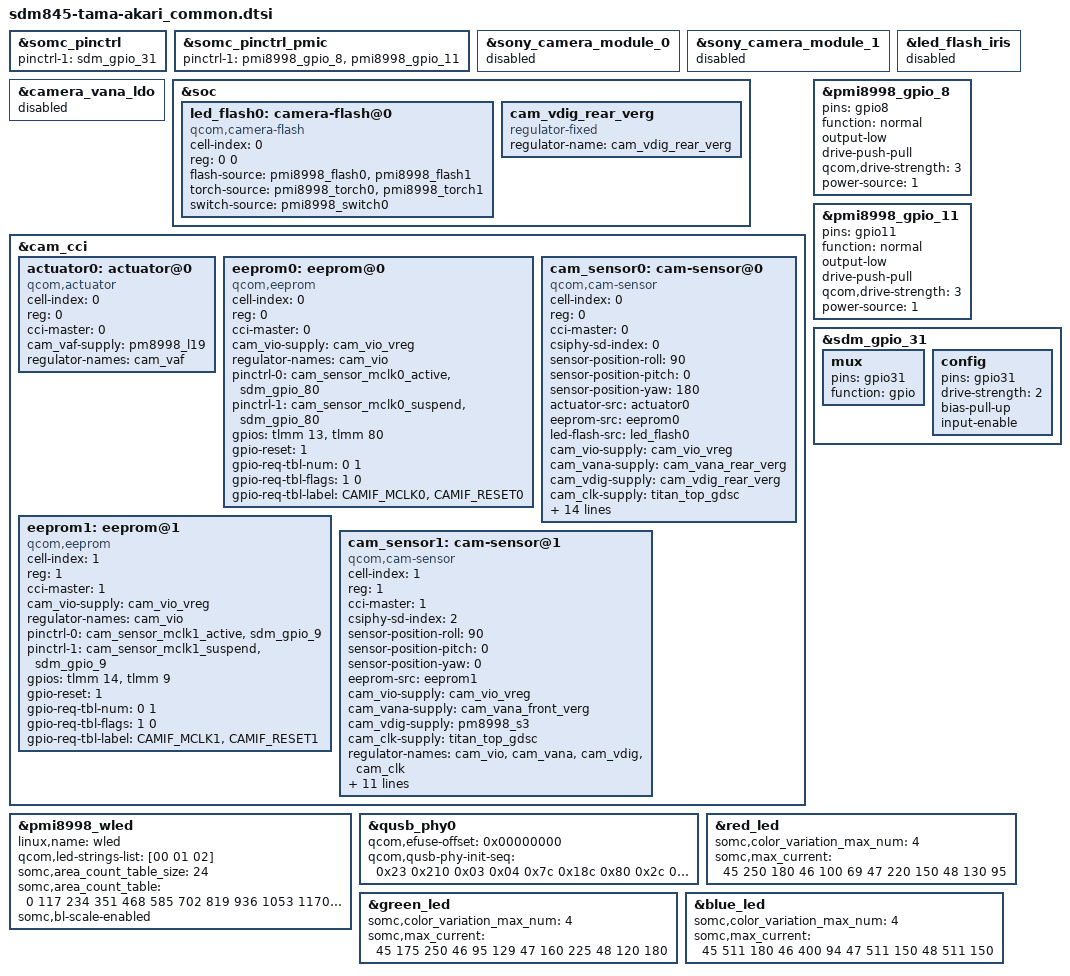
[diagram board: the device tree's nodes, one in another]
/* arch/arm64/boot/dts/somc/sdm845-tama-akari_common.dtsi
 *
 * This program is free software; you can redistribute it and/or modify
 * it under the terms of the GNU General Public License version 2 and
 * only version 2 as published by the Free Software Foundation.
 *
 * This program is distributed in the hope that it will be useful,
 * but WITHOUT ANY WARRANTY; without even the implied warranty of
 * MERCHANTABILITY or FITNESS FOR A PARTICULAR PURPOSE.  See the
 * GNU General Public License for more details.
 */
/*
 * Copyright (C) 2017 Sony Mobile Communications Inc.
 *
 * This program is free software; you can redistribute it and/or modify
 * it under the terms of the GNU General Public License version 2, as
 * published by the Free Software Foundation.
 */

#include "sdm845-tama-common.dtsi"


&somc_pinctrl {
	/* If product common default setting is needed,
	fill pinctrl-1 value in <product>_common.dtsi */
	pinctrl-1 = <&sdm_gpio_31>;
};

&somc_pinctrl_pmic {
	/* If product common PMIC default setting is needed,
	fill pinctrl-1 value in <product>_common.dtsi */
	pinctrl-1 = <&pmi8998_gpio_8 &pmi8998_gpio_11>;
};

/*
 * The stock Sony camera stack uses sony_camera_module_0/1.  The SODP CamX
 * stack enumerates the standard Qualcomm camera entities instead.  These
 * nodes mirror the camera fragments from Sony's Pie v9 Akari DTBO while
 * leaving the rest of the SOV37/KDDI device tree untouched.
 */
&sony_camera_module_0 {
	status = "disabled";
};

&sony_camera_module_1 {
	status = "disabled";
};

&led_flash_iris {
	status = "disabled";
};

&camera_vana_ldo {
	status = "disabled";
};

&soc {
	led_flash0: camera-flash@0 {
		cell-index = <0>;
		reg = <0 0>;
		compatible = "qcom,camera-flash";
		flash-source = <&pmi8998_flash0 &pmi8998_flash1>;
		torch-source = <&pmi8998_torch0 &pmi8998_torch1>;
		switch-source = <&pmi8998_switch0>;
		status = "ok";
	};

	cam_vdig_rear_verg: cam_vdig_rear_verg {
		compatible = "regulator-fixed";
		regulator-name = "cam_vdig_rear_verg";
	};
};

&cam_cci {
	actuator0: actuator@0 {
		cell-index = <0>;
		compatible = "qcom,actuator";
		reg = <0>;
		cci-master = <0>;
		cam_vaf-supply = <&pm8998_l19>;
		regulator-names = "cam_vaf";
	};

	eeprom0: eeprom@0 {
		cell-index = <0>;
		compatible = "qcom,eeprom";
		reg = <0>;
		cci-master = <0>;
		cam_vio-supply = <&cam_vio_vreg>;
		regulator-names = "cam_vio";
		pinctrl-names = "cam_default", "cam_suspend";
		pinctrl-0 = <&cam_sensor_mclk0_active &sdm_gpio_80>;
		pinctrl-1 = <&cam_sensor_mclk0_suspend &sdm_gpio_80>;
		gpios = <&tlmm 13 0>, <&tlmm 80 0>;
		gpio-reset = <1>;
		gpio-req-tbl-num = <0 1>;
		gpio-req-tbl-flags = <1 0>;
		gpio-req-tbl-label = "CAMIF_MCLK0", "CAMIF_RESET0";
		status = "ok";
	};

	cam_sensor0: cam-sensor@0 {
		cell-index = <0>;
		compatible = "qcom,cam-sensor";
		reg = <0>;
		cci-master = <0>;
		csiphy-sd-index = <0>;
		sensor-position-roll = <90>;
		sensor-position-pitch = <0>;
		sensor-position-yaw = <180>;
		actuator-src = <&actuator0>;
		eeprom-src = <&eeprom0>;
		led-flash-src = <&led_flash0>;
		cam_vio-supply = <&cam_vio_vreg>;
		cam_vana-supply = <&cam_vana_rear_verg>;
		cam_vdig-supply = <&cam_vdig_rear_verg>;
		cam_clk-supply = <&titan_top_gdsc>;
		regulator-names = "cam_vio", "cam_vana", "cam_vdig", "cam_clk";
		pinctrl-names = "cam_default", "cam_suspend";
		pinctrl-0 = <&cam_sensor_mclk0_active &sdm_gpio_80>;
		pinctrl-1 = <&cam_sensor_mclk0_suspend &sdm_gpio_80>;
		gpios = <&tlmm 13 0>, <&tlmm 80 0>;
		gpio-reset = <1>;
		gpio-req-tbl-num = <0 1>;
		gpio-req-tbl-flags = <1 0>;
		gpio-req-tbl-label = "CAMIF_MCLK0", "CAMIF_RESET0";
		clocks = <&clock_camcc CAM_CC_MCLK0_CLK>;
		clock-names = "cam_clk";
		clock-cntl-level = "turbo";
		clock-rates = <8000000>;
		status = "ok";
	};

	eeprom1: eeprom@1 {
		cell-index = <1>;
		compatible = "qcom,eeprom";
		reg = <1>;
		cci-master = <1>;
		cam_vio-supply = <&cam_vio_vreg>;
		regulator-names = "cam_vio";
		pinctrl-names = "cam_default", "cam_suspend";
		pinctrl-0 = <&cam_sensor_mclk1_active &sdm_gpio_9>;
		pinctrl-1 = <&cam_sensor_mclk1_suspend &sdm_gpio_9>;
		gpios = <&tlmm 14 0>, <&tlmm 9 0>;
		gpio-reset = <1>;
		gpio-req-tbl-num = <0 1>;
		gpio-req-tbl-flags = <1 0>;
		gpio-req-tbl-label = "CAMIF_MCLK1", "CAMIF_RESET1";
		status = "ok";
	};

	cam_sensor1: cam-sensor@1 {
		cell-index = <1>;
		compatible = "qcom,cam-sensor";
		reg = <1>;
		cci-master = <1>;
		csiphy-sd-index = <2>;
		sensor-position-roll = <90>;
		sensor-position-pitch = <0>;
		sensor-position-yaw = <0>;
		eeprom-src = <&eeprom1>;
		cam_vio-supply = <&cam_vio_vreg>;
		cam_vana-supply = <&cam_vana_front_verg>;
		cam_vdig-supply = <&pm8998_s3>;
		cam_clk-supply = <&titan_top_gdsc>;
		regulator-names = "cam_vio", "cam_vana", "cam_vdig", "cam_clk";
		pinctrl-names = "cam_default", "cam_suspend";
		pinctrl-0 = <&cam_sensor_mclk1_active &sdm_gpio_9>;
		pinctrl-1 = <&cam_sensor_mclk1_suspend &sdm_gpio_9>;
		gpios = <&tlmm 14 0>, <&tlmm 9 0>;
		gpio-reset = <1>;
		gpio-req-tbl-num = <0 1>;
		gpio-req-tbl-flags = <1 0>;
		gpio-req-tbl-label = "CAMIF_MCLK1", "CAMIF_RESET1";
		clocks = <&clock_camcc CAM_CC_MCLK1_CLK>;
		clock-names = "cam_clk";
		clock-cntl-level = "turbo";
		clock-rates = <8000000>;
		status = "ok";
	};
};

/* GPIO_8: WLC_EN_N */
&pmi8998_gpio_8 {
	pins = "gpio8";
	function = "normal";
	/delete-property/ bias-high-impedance;
	output-low;
	drive-push-pull;
	qcom,drive-strength = <3>;
	power-source = <1>;
};

/* GPIO_11: RSVD(WLC_EN_N) */
&pmi8998_gpio_11 {
	pins = "gpio11";
	function = "normal";
	/delete-property/ bias-high-impedance;
	output-low;
	drive-push-pull;
	qcom,drive-strength = <3>;
	power-source = <1>;
};

/* GPIO_31 : WLC_INT_N */
&sdm_gpio_31 {
	mux {
		pins = "gpio31";
		function = "gpio";
	};
	config {
		pins = "gpio31";
		drive-strength = <2>;
		/delete-property/ bias-pull-down;
		bias-pull-up;
		input-enable;
	};
};

&pmi8998_wled {
	linux,name = "wled";
	qcom,led-strings-list = [00 01 02];
	somc,area_count_table_size = <24>;
	somc,area_count_table = <0 117 234 351 468 585 702 819
				936 1053 1170 1404 1638 1872 2106
				2340 2574 2808 3042 3276 3510
				3744 3978 4095>;
	somc,bl-scale-enabled;
};

&qusb_phy0 {
	qcom,efuse-offset = <0x00000000>;
	qcom,qusb-phy-init-seq =
		/* <value reg_offset> */
		   <0x23 0x210 /* PWR_CTRL1 */
		    0x03 0x04  /* PLL_ANALOG_CONTROLS_TWO */
		    0x7c 0x18c /* PLL_CLOCK_INVERTERS */
		    0x80 0x2c  /* PLL_CMODE */
		    0x0a 0x184 /* PLL_LOCK_DELAY */
		    0x19 0xb4  /* PLL_DIGITAL_TIMERS_TWO */
		    0x40 0x194 /* PLL_BIAS_CONTROL_1 */
		    0x16 0x198 /* PLL_BIAS_CONTROL_2 */
		    0x21 0x214 /* PWR_CTRL2 */
		    0x08 0x220 /* IMP_CTRL1 */
		    0x58 0x224 /* IMP_CTRL2 */
		    0x75 0x240 /* TUNE1 */
		    0x2B 0x244 /* TUNE2 */
		    0xca 0x248 /* TUNE3 */
		    0x04 0x24c /* TUNE4 */
		    0x01 0x250 /* TUNE5 */
		    0x00 0x23c /* CHG_CTRL2 */
		    0x22 0x210>; /* PWR_CTRL1 */
};

&red_led {
	somc,color_variation_max_num = <4>;
	somc,max_current = <
		45 250 180
		46 100 69
		47 220 150
		48 130 95>;
};

&green_led {
	somc,color_variation_max_num = <4>;
	somc,max_current = <
		45 175 250
		46 95 129
		47 160 225
		48 120 180>;
};

&blue_led {
	somc,color_variation_max_num = <4>;
	somc,max_current = <
		45 511 180
		46 400 94
		47 511 150
		48 511 150>;
};

#include "dsi-panel-akari.dtsi"
#include "somc-tama-display.dtsi"
#include "somc-tama-display_akari.dtsi"
#include "somc-tama-touch.dtsi"
#include "somc-tama-touch_akari.dtsi"
#include "charger-tama-common.dtsi"
#include "charger-tama-akari.dtsi"
